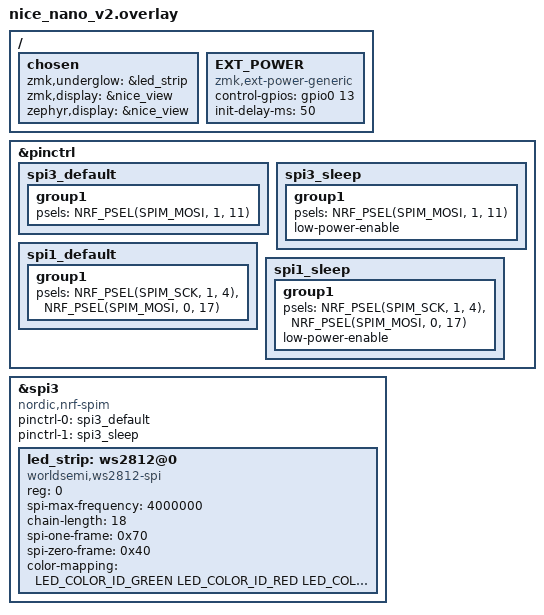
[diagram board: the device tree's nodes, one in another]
#include <dt-bindings/led/led.h>

&pinctrl {
    spi3_default: spi3_default {
        group1 {
            psels = <NRF_PSEL(SPIM_MOSI, 1, 11)>;
        };
    };

    spi3_sleep: spi3_sleep {
        group1 {
            psels = <NRF_PSEL(SPIM_MOSI, 1, 11)>;
            low-power-enable;
        };
    };
	
	 spi1_default: spi1_default {
        group1 {
            psels = <NRF_PSEL(SPIM_SCK,  1, 4)>,
                    <NRF_PSEL(SPIM_MOSI, 0, 17)>;
        };
    };

    spi1_sleep: spi1_sleep {
        group1 {
            psels = <NRF_PSEL(SPIM_SCK,  1, 4)>,
                    <NRF_PSEL(SPIM_MOSI, 0, 17)>;
            low-power-enable;
        };
    };
};

&spi3 {
    compatible = "nordic,nrf-spim";
    status = "okay";

    pinctrl-0 = <&spi3_default>;
    pinctrl-1 = <&spi3_sleep>;
    pinctrl-names = "default", "sleep";

    led_strip: ws2812@0 {
        compatible = "worldsemi,ws2812-spi";

        /* SPI */
        reg = <0>; /* ignored, but necessary for SPI bindings */
        spi-max-frequency = <4000000>;

        /* WS2812 */
        chain-length = <18>; /* arbitrary; change at will */
        spi-one-frame = <0x70>;
        spi-zero-frame = <0x40>;

        color-mapping = <LED_COLOR_ID_GREEN LED_COLOR_ID_RED LED_COLOR_ID_BLUE>;
    };
};

/ {
    chosen {
        zmk,underglow = &led_strip;
		zmk,display = &nice_view;
		zephyr,display = &nice_view;  
    };
	
	EXT_POWER {
        compatible = "zmk,ext-power-generic";
        control-gpios = <&gpio0 13 GPIO_ACTIVE_HIGH>;
        init-delay-ms = <50>;
    };
};
